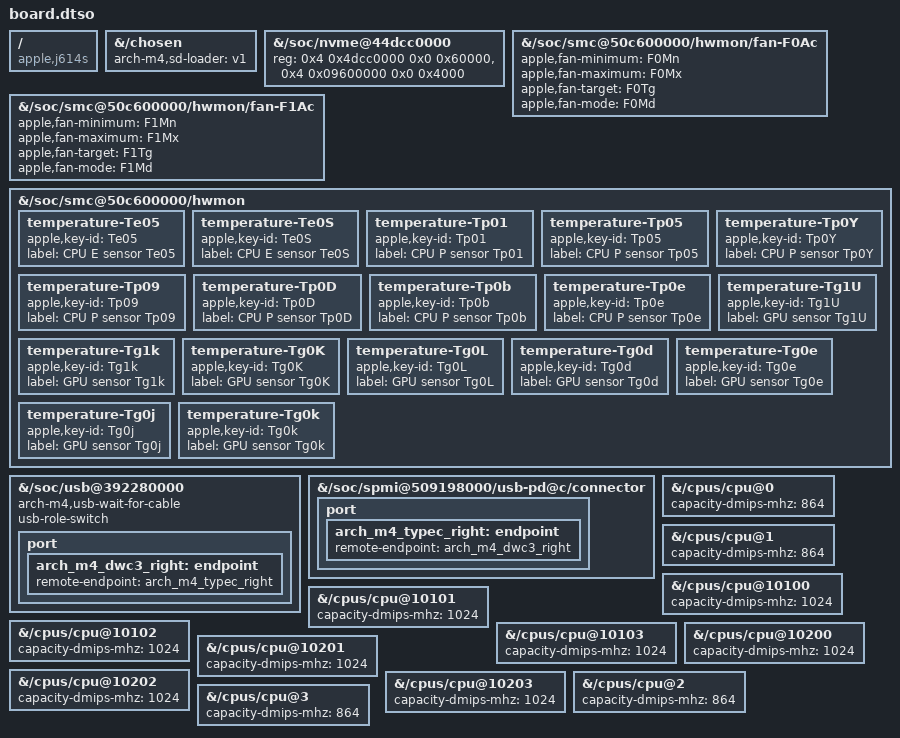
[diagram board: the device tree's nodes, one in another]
/dts-v1/;
/plugin/;
/ {
    compatible = "apple,j614s";
    fragment@0 {
        target-path = "/chosen";
        __overlay__ {
            arch-m4,sd-loader = "v1";
        };
    };
    /* Yureka's v2 T8132 NVMe driver uses the extended controller aperture
     * for both NVMe and NVMMU. The old loader's baseline only maps 64 KiB;
     * change the Linux mapping on SD, retaining m1n1's live handoff data. */
    fragment@1 {
        target-path = "/soc/nvme@44dcc0000";
        __overlay__ {
            reg = <0x4 0x4dcc0000 0x0 0x60000>,
                  <0x4 0x09600000 0x0 0x4000>;
            reg-names = "nvme", "ans";
        };
    };
    /* Asahi's dual-fan key schema, read-only verified on this J614s on
     * 2026-10-05. The driver leaves fan_control=false by default; merely
     * describing these keys does not change firmware's current fan mode. */
    fragment@2 {
        target-path = "/soc/smc@50c600000/hwmon/fan-F0Ac";
        __overlay__ {
            apple,fan-minimum = "F0Mn";
            apple,fan-maximum = "F0Mx";
            apple,fan-target = "F0Tg";
            apple,fan-mode = "F0Md";
        };
    };
    fragment@3 {
        target-path = "/soc/smc@50c600000/hwmon/fan-F1Ac";
        __overlay__ {
            apple,fan-minimum = "F1Mn";
            apple,fan-maximum = "F1Mx";
            apple,fan-target = "F1Tg";
            apple,fan-mode = "F1Md";
        };
    };
    /* M4 sensor families documented by Stats and independently read on this
     * J614s. Names identify sensors, not Linux CPU numbers. Missing keys from
     * the published list were deliberately omitted. */
    fragment@4 {
        target-path = "/soc/smc@50c600000/hwmon";
        __overlay__ {
            temperature-Te05 { apple,key-id = "Te05"; label = "CPU E sensor Te05"; };
            temperature-Te0S { apple,key-id = "Te0S"; label = "CPU E sensor Te0S"; };
            temperature-Tp01 { apple,key-id = "Tp01"; label = "CPU P sensor Tp01"; };
            temperature-Tp05 { apple,key-id = "Tp05"; label = "CPU P sensor Tp05"; };
            temperature-Tp09 { apple,key-id = "Tp09"; label = "CPU P sensor Tp09"; };
            temperature-Tp0D { apple,key-id = "Tp0D"; label = "CPU P sensor Tp0D"; };
            temperature-Tp0Y { apple,key-id = "Tp0Y"; label = "CPU P sensor Tp0Y"; };
            temperature-Tp0b { apple,key-id = "Tp0b"; label = "CPU P sensor Tp0b"; };
            temperature-Tp0e { apple,key-id = "Tp0e"; label = "CPU P sensor Tp0e"; };
            temperature-Tg1U { apple,key-id = "Tg1U"; label = "GPU sensor Tg1U"; };
            temperature-Tg1k { apple,key-id = "Tg1k"; label = "GPU sensor Tg1k"; };
            temperature-Tg0K { apple,key-id = "Tg0K"; label = "GPU sensor Tg0K"; };
            temperature-Tg0L { apple,key-id = "Tg0L"; label = "GPU sensor Tg0L"; };
            temperature-Tg0d { apple,key-id = "Tg0d"; label = "GPU sensor Tg0d"; };
            temperature-Tg0e { apple,key-id = "Tg0e"; label = "GPU sensor Tg0e"; };
            temperature-Tg0j { apple,key-id = "Tg0j"; label = "GPU sensor Tg0j"; };
            temperature-Tg0k { apple,key-id = "Tg0k"; label = "GPU sensor Tg0k"; };
        };
    };
    /* The enrolled baseline predates working Type-C transport and forces
     * DWC3 on at probe. Keep those enrolled bytes: this SD-only marker tells
     * the patched driver to wait for the PD cable event instead. The PD chip
     * resets the eUSB2 repeater on attachment, so early PHY setup is stale.
     * This graph carries USB2 role events for the right port only. */
    fragment@5 {
        target-path = "/soc/usb@392280000";
        __overlay__ {
            arch-m4,usb-wait-for-cable;
            usb-role-switch;
            port {
                arch_m4_dwc3_right: endpoint {
                    remote-endpoint = <&arch_m4_typec_right>;
                };
            };
        };
    };
    fragment@6 {
        target-path = "/soc/spmi@509198000/usb-pd@c/connector";
        __overlay__ {
            port {
                arch_m4_typec_right: endpoint {
                    remote-endpoint = <&arch_m4_dwc3_right>;
                };
            };
        };
    };
    /* Provisional J614s scheduler capacities: P=1024, E=864 per MHz.
     * With declared maximum OPPs4512/2592MHz, normalized P=1024/E~496.
     * Provisional observed throughput weights, not silicon calibration.
     * All12 CPUs must have values. No frequency, idle or power policy changes. */
    fragment@7 {
        target-path = "/cpus/cpu@0";
        __overlay__ { capacity-dmips-mhz = <864>; };
    };
    fragment@8 {
        target-path = "/cpus/cpu@1";
        __overlay__ { capacity-dmips-mhz = <864>; };
    };
    fragment@9 {
        target-path = "/cpus/cpu@10100";
        __overlay__ { capacity-dmips-mhz = <1024>; };
    };
    fragment@10 {
        target-path = "/cpus/cpu@10101";
        __overlay__ { capacity-dmips-mhz = <1024>; };
    };
    fragment@11 {
        target-path = "/cpus/cpu@10102";
        __overlay__ { capacity-dmips-mhz = <1024>; };
    };
    fragment@12 {
        target-path = "/cpus/cpu@10103";
        __overlay__ { capacity-dmips-mhz = <1024>; };
    };
    fragment@13 {
        target-path = "/cpus/cpu@10200";
        __overlay__ { capacity-dmips-mhz = <1024>; };
    };
    fragment@14 {
        target-path = "/cpus/cpu@10201";
        __overlay__ { capacity-dmips-mhz = <1024>; };
    };
    fragment@15 {
        target-path = "/cpus/cpu@10202";
        __overlay__ { capacity-dmips-mhz = <1024>; };
    };
    fragment@16 {
        target-path = "/cpus/cpu@10203";
        __overlay__ { capacity-dmips-mhz = <1024>; };
    };
    fragment@17 {
        target-path = "/cpus/cpu@2";
        __overlay__ { capacity-dmips-mhz = <864>; };
    };
    fragment@18 {
        target-path = "/cpus/cpu@3";
        __overlay__ { capacity-dmips-mhz = <864>; };
    };
};
